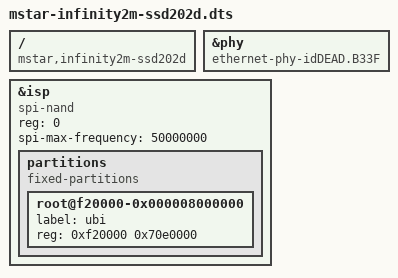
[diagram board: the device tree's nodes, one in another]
// SPDX-License-Identifier: GPL-2.0
/*
 * Copyright (c) 2020 thingy.jp.
 * Author: Daniel Palmer <daniel@0x0f.com>
 */

/dts-v1/;

#include "mstar-infinity2m-ssd20xd.dtsi"
#include "mstar-infinity2m-ssd202d.dtsi"

/ {
        compatible = "mstar,infinity2m-ssd202d", "mstar,infinity2m-ssd20xd",
		     "mstar,infinity2m", "mstar,mstar-v7";
};

&phy {
	compatible = "ethernet-phy-idDEAD.B33F";
};

&isp {
	#address-cells = <1>;
	#size-cells = <1>;
	compatible = "spi-nand";
	reg = <0>;
	spi-max-frequency = <50000000>;
	partitions {
		compatible = "fixed-partitions";
		#address-cells = <1>;
		#size-cells = <1>;
		root@f20000-0x000008000000 {
			label = "ubi";
			reg = <0xf20000 0x70e0000>;
		};
	};
};
